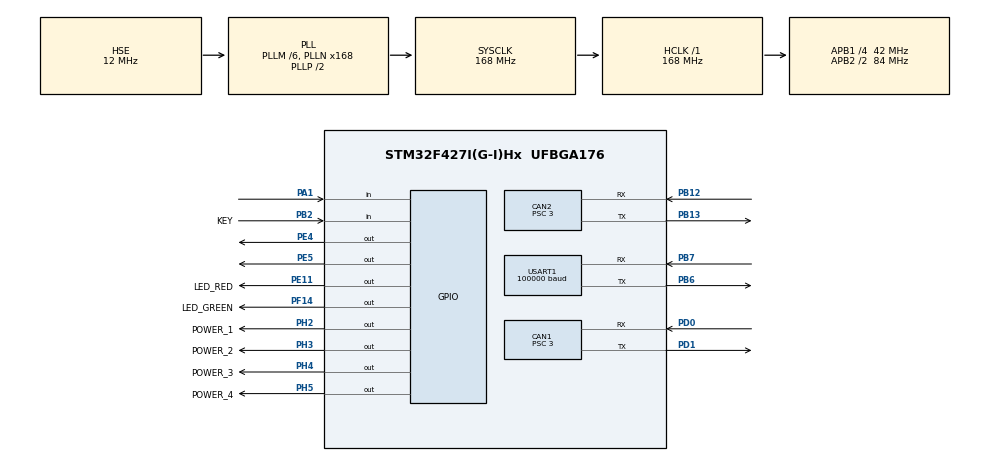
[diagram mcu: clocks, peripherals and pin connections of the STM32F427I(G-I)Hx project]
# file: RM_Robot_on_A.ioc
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CAN1.BS1=CAN_BS1_9TQ
CAN1.BS2=CAN_BS2_4TQ
CAN1.CalculateBaudRate=1000000
CAN1.CalculateTimeBit=1000
CAN1.CalculateTimeQuantum=71.42857142857143
CAN1.Prescaler=3
CAN2.BS1=CAN_BS1_9TQ
CAN2.BS2=CAN_BS2_4TQ
CAN2.CalculateBaudRate=1000000
CAN2.CalculateTimeBit=1000
CAN2.CalculateTimeQuantum=71.42857142857143
CAN2.Prescaler=3
Dma.Request0=USART1_RX
Dma.USART1_RX.0.Direction=DMA_PERIPH_TO_MEMORY
Dma.USART1_RX.0.FIFOMode=DMA_FIFOMODE_DISABLE
Dma.USART1_RX.0.Instance=DMA2_Stream2
Dma.USART1_RX.0.MemDataAlignment=DMA_MDATAALIGN_BYTE
Dma.USART1_RX.0.MemInc=DMA_MINC_ENABLE
Dma.USART1_RX.0.Mode=DMA_NORMAL
Dma.USART1_RX.0.PeriphDataAlignment=DMA_PDATAALIGN_BYTE
Dma.USART1_RX.0.PeriphInc=DMA_PINC_DISABLE
Dma.USART1_RX.0.Priority=DMA_PRIORITY_LOW
FREERTOS.Tasks01=led_RGB_flow,-3,128,led_RGB_flow_task,As weak,NULL,Dynamic,NULL,NULL;Motor_cmd,0,128,Motor_cmd_task,As weak,NULL,Dynamic,NULL,NULL
Mcu.Family=STM32F4
Mcu.Name=STM32F427I(G-I)Hx
Mcu.Package=UFBGA176
NVIC.CAN1_RX0_IRQn=true\:5\:0\:false\:false\:true\:true\:true\:true\:true
NVIC.CAN1_TX_IRQn=true\:5\:0\:false\:false\:true\:true\:true\:true\:true
NVIC.CAN2_RX0_IRQn=true\:5\:0\:false\:false\:true\:true\:true\:true\:true
NVIC.CAN2_TX_IRQn=true\:5\:0\:false\:false\:true\:true\:true\:true\:true
NVIC.DMA2_Stream2_IRQn=true\:5\:0\:false\:false\:true\:true\:false\:true\:true
NVIC.PriorityGroup=NVIC_PRIORITYGROUP_4
NVIC.USART1_IRQn=true\:5\:0\:false\:false\:false\:true\:true\:true\:true
PA1.GPIO_PuPd=GPIO_PULLDOWN
PA1.Signal=GPIO_Input
PA13.Mode=Serial_Wire
PA13.Signal=SYS_JTMS-SWDIO
PA14.Mode=Serial_Wire
PA14.Signal=SYS_JTCK-SWCLK
PB12.Mode=CAN_Activate
PB12.Signal=CAN2_RX
PB13.Mode=CAN_Activate
PB13.Signal=CAN2_TX
PB2/BOOT1.GPIO_Label=KEY
PB2/BOOT1.Signal=GPIO_Input
PB6.Mode=Asynchronous
PB6.Signal=USART1_TX
PB7.Mode=Asynchronous
PB7.Signal=USART1_RX
PD0.Mode=CAN_Activate
PD0.Signal=CAN1_RX
PD1.Mode=CAN_Activate
PD1.Signal=CAN1_TX
PE11.GPIO_Label=LED_RED
PE11.Signal=GPIO_Output
PE4.GPIO_PuPd=GPIO_PULLDOWN
PE4.Signal=GPIO_Output
PE5.GPIO_PuPd=GPIO_PULLDOWN
PE5.Signal=GPIO_Output
PF14.GPIO_Label=LED_GREEN
PF14.Signal=GPIO_Output
PH0/OSC_IN.Mode=HSE-External-Oscillator
PH0/OSC_IN.Signal=RCC_OSC_IN
PH1/OSC_OUT.Mode=HSE-External-Oscillator
PH1/OSC_OUT.Signal=RCC_OSC_OUT
PH2.GPIO_Label=POWER_1
PH2.Signal=GPIO_Output
PH3.GPIO_Label=POWER_2
PH3.Signal=GPIO_Output
PH4.GPIO_Label=POWER_3
PH4.Signal=GPIO_Output
PH5.GPIO_Label=POWER_4
PH5.Signal=GPIO_Output
ProjectManager.HeapSize=0x200
ProjectManager.StackSize=0x400
ProjectManager.TargetToolchain=MDK-ARM V5
RCC.48MHZClocksFreq_Value=84000000
RCC.AHBFreq_Value=168000000
RCC.APB1CLKDivider=RCC_HCLK_DIV4
RCC.APB1Freq_Value=42000000
RCC.APB1TimFreq_Value=84000000
RCC.APB2CLKDivider=RCC_HCLK_DIV2
RCC.APB2Freq_Value=84000000
RCC.APB2TimFreq_Value=168000000
RCC.CortexFreq_Value=168000000
RCC.HCLKFreq_Value=168000000
RCC.HSE_VALUE=12000000
RCC.HSI_VALUE=16000000
RCC.LSE_VALUE=32768
RCC.PLLM=6
RCC.PLLN=168
RCC.PLLSourceVirtual=RCC_PLLSOURCE_HSE
RCC.SYSCLKFreq_VALUE=168000000
RCC.SYSCLKSource=RCC_SYSCLKSOURCE_PLLCLK
RCC.VCOOutputFreq_Value=336000000
USART1.BaudRate=100000
USART1.Parity=PARITY_EVEN
USART1.VirtualMode=VM_ASYNC
VP_FREERTOS_VS_CMSIS_V1.Mode=CMSIS_V1
board=custom

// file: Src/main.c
/* USER CODE BEGIN Header */
/**
  ******************************************************************************
  * @file           : main.c
  * @brief          : Main program body
  ******************************************************************************
  * @attention
  *
  * <h2><center>&copy; Copyright (c) 2022 STMicroelectronics.
  * All rights reserved.</center></h2>
  *
  * This software component is licensed by ST under BSD 3-Clause license,
  * the "License"; You may not use this file except in compliance with the
  * License. You may obtain a copy of the License at:
  *                        opensource.org/licenses/BSD-3-Clause
  *
  ******************************************************************************
  */
/* USER CODE END Header */
#include "main.h"
#include "cmsis_os.h"
#include "can.h"
#include "dma.h"
#include "usart.h"
#include "gpio.h"

/* USER CODE BEGIN Includes */
#include "bsp_can.h"
#include "pid.h"
#include "remote_control.h"
#include "led_flow_task.h"
#include "Motor_cmd_Task.h"
/* USER CODE END Includes */

/* USER CODE BEGIN PM */
extern uint8_t UART_Buffer[100];
/* USER CODE END PM */

void SystemClock_Config(void);
void MX_FREERTOS_Init(void);

int main(void)
{

  /* MCU Configuration--------------------------------------------------------*/

  /* Reset of all peripherals, Initializes the Flash interface and the Systick. */
  HAL_Init();

  /* Configure the system clock */
  SystemClock_Config();

  /* Initialize all configured peripherals */
  MX_GPIO_Init();
  MX_CAN1_Init();
  MX_CAN2_Init();
  MX_DMA_Init();
  MX_USART1_UART_Init();
  /* USER CODE BEGIN 2 */
 HAL_GPIO_WritePin(POWER_4_GPIO_Port,POWER_4_Pin,GPIO_PIN_SET);
	HAL_UART_Receive_IT_IDLE(&huart1,UART_Buffer,100);   //启动串口3接收
  /* USER CODE END 2 */

  /* Call init function for freertos objects (in freertos.c) */
  MX_FREERTOS_Init();
  /* Start scheduler */
  osKernelStart();

  /* We should never get here as control is now taken by the scheduler */
  /* Infinite loop */
  while (1)
  {

  }
}

void SystemClock_Config(void)
{
  RCC_OscInitTypeDef RCC_OscInitStruct = {0};
  RCC_ClkInitTypeDef RCC_ClkInitStruct = {0};

  /** Configure the main internal regulator output voltage
  */
  __HAL_RCC_PWR_CLK_ENABLE();
  __HAL_PWR_VOLTAGESCALING_CONFIG(PWR_REGULATOR_VOLTAGE_SCALE1);
  /** Initializes the RCC Oscillators according to the specified parameters
  * in the RCC_OscInitTypeDef structure.
  */
  RCC_OscInitStruct.OscillatorType = RCC_OSCILLATORTYPE_HSE;
  RCC_OscInitStruct.HSEState = RCC_HSE_ON;
  RCC_OscInitStruct.PLL.PLLState = RCC_PLL_ON;
  RCC_OscInitStruct.PLL.PLLSource = RCC_PLLSOURCE_HSE;
  RCC_OscInitStruct.PLL.PLLM = 6;
  RCC_OscInitStruct.PLL.PLLN = 168;
  RCC_OscInitStruct.PLL.PLLP = RCC_PLLP_DIV2;
  RCC_OscInitStruct.PLL.PLLQ = 4;
  if (HAL_RCC_OscConfig(&RCC_OscInitStruct) != HAL_OK)
  {
    Error_Handler();
  }
  /** Initializes the CPU, AHB and APB buses clocks
  */
  RCC_ClkInitStruct.ClockType = RCC_CLOCKTYPE_HCLK|RCC_CLOCKTYPE_SYSCLK
                              |RCC_CLOCKTYPE_PCLK1|RCC_CLOCKTYPE_PCLK2;
  RCC_ClkInitStruct.SYSCLKSource = RCC_SYSCLKSOURCE_PLLCLK;
  RCC_ClkInitStruct.AHBCLKDivider = RCC_SYSCLK_DIV1;
  RCC_ClkInitStruct.APB1CLKDivider = RCC_HCLK_DIV4;
  RCC_ClkInitStruct.APB2CLKDivider = RCC_HCLK_DIV2;

  if (HAL_RCC_ClockConfig(&RCC_ClkInitStruct, FLASH_LATENCY_5) != HAL_OK)
  {
    Error_Handler();
  }
}

void Error_Handler(void)
{
  __disable_irq();
  while (1)
  {
  }
}

/************************ (C) COPYRIGHT STMicroelectronics *****END OF FILE****/

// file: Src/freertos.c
/* USER CODE BEGIN Header */
/**
  ******************************************************************************
  * File Name          : freertos.c
  * Description        : Code for freertos applications
  ******************************************************************************
  * @attention
  *
  * <h2><center>&copy; Copyright (c) 2022 STMicroelectronics.
  * All rights reserved.</center></h2>
  *
  * This software component is licensed by ST under Ultimate Liberty license
  * SLA0044, the "License"; You may not use this file except in compliance with
  * the License. You may obtain a copy of the License at:
  *                             www.st.com/SLA0044
  *
  ******************************************************************************
  */
/* USER CODE END Header */

#include "FreeRTOS.h"
#include "task.h"
#include "main.h"
#include "cmsis_os.h"

/* USER CODE BEGIN Includes */
#include "Motor_cmd_Task.h"
#include "led_flow_task.h"
/* USER CODE END Includes */

osThreadId led_RGB_flowHandle;
osThreadId Motor_cmdHandle;

void led_RGB_flow_task(void const * argument);
void Motor_cmd_task(void const * argument);

void MX_FREERTOS_Init(void); /* (MISRA C 2004 rule 8.1) */

/* GetIdleTaskMemory prototype (linked to static allocation support) */
void vApplicationGetIdleTaskMemory( StaticTask_t **ppxIdleTaskTCBBuffer, StackType_t **ppxIdleTaskStackBuffer, uint32_t *pulIdleTaskStackSize );

/* USER CODE BEGIN GET_IDLE_TASK_MEMORY */
static StaticTask_t xIdleTaskTCBBuffer;
static StackType_t xIdleStack[configMINIMAL_STACK_SIZE];

void vApplicationGetIdleTaskMemory( StaticTask_t **ppxIdleTaskTCBBuffer, StackType_t **ppxIdleTaskStackBuffer, uint32_t *pulIdleTaskStackSize )
{
  *ppxIdleTaskTCBBuffer = &xIdleTaskTCBBuffer;
  *ppxIdleTaskStackBuffer = &xIdleStack[0];
  *pulIdleTaskStackSize = configMINIMAL_STACK_SIZE;
  /* place for user code */
}
/* USER CODE END GET_IDLE_TASK_MEMORY */

void MX_FREERTOS_Init(void) {

  /* Create the thread(s) */
  /* definition and creation of led_RGB_flow */
  osThreadDef(led_RGB_flow, led_RGB_flow_task, osPriorityIdle, 0, 128);
  led_RGB_flowHandle = osThreadCreate(osThread(led_RGB_flow), NULL);

  /* definition and creation of Motor_cmd */
  osThreadDef(Motor_cmd, Motor_cmd_task, osPriorityNormal, 0, 128);
  Motor_cmdHandle = osThreadCreate(osThread(Motor_cmd), NULL);

}

__weak void led_RGB_flow_task(void const * argument)
{
  for(;;)
  {
    osDelay(1);
  }
}

__weak void Motor_cmd_task(void const * argument)
{
  for(;;)
  {
    osDelay(1);
  }
}

/************************ (C) COPYRIGHT STMicroelectronics *****END OF FILE****/
